# STM32F031C4T6 register map
File version: 1.0
Registers are 32-bit, access not given, reset 0x0 unless marked. A register's access mark holds for its fields unless they carry their own. Offsets are from the block's base; [hi:lo] are bit positions; {n}, {i} and the like mark numbered series.

## CRS
Base 0x40006C00
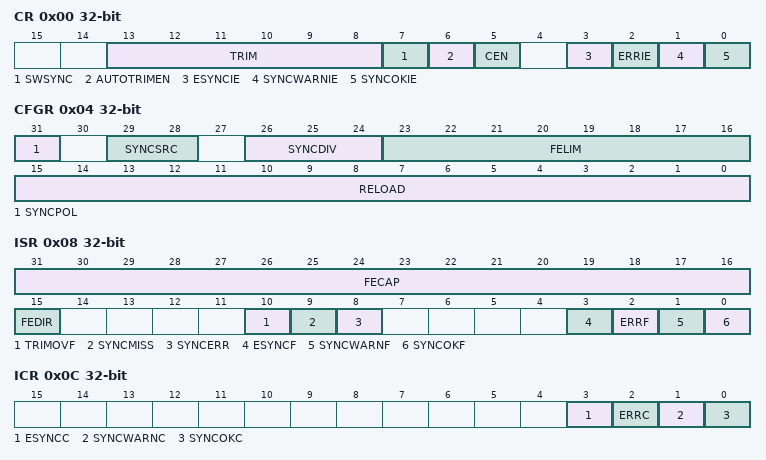
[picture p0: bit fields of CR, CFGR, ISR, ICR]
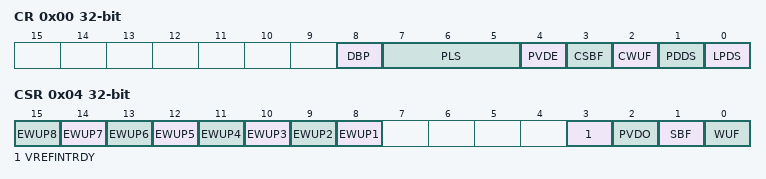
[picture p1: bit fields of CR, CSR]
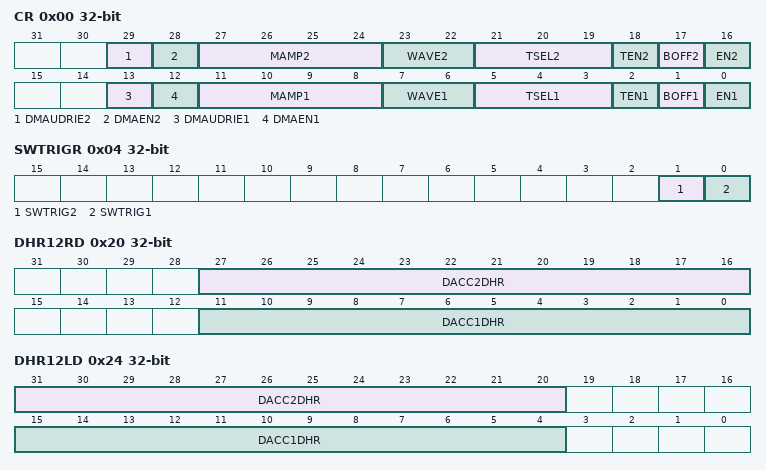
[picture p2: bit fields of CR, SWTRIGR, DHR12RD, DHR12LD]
0x00 CR
  [13:8] TRIM, [7] SWSYNC, [6] AUTOTRIMEN, [5] CEN, [3] ESYNCIE, [2] ERRIE, [1] SYNCWARNIE, [0] SYNCOKIE
0x04 CFGR
  [31] SYNCPOL, [29:28] SYNCSRC, [26:24] SYNCDIV, [23:16] FELIM, [15:0] RELOAD
0x08 ISR
  [31:16] FECAP, [15] FEDIR, [10] TRIMOVF, [9] SYNCMISS, [8] SYNCERR, [3] ESYNCF, [2] ERRF, [1] SYNCWARNF, [0] SYNCOKF
0x0C ICR
  [3] ESYNCC, [2] ERRC, [1] SYNCWARNC, [0] SYNCOKC

## PWR
Base 0x40007000
0x00 CR
  [8] DBP, [7:5] PLS, [4] PVDE, [3] CSBF, [2] CWUF, [1] PDDS, [0] LPDS
0x04 CSR
  [n+7] EWUP{n} (n=1..8), [3] VREFINTRDY, [2] PVDO, [1] SBF, [0] WUF

## DAC
Base 0x40007400
0x00 CR
  [29] DMAUDRIE2, [28] DMAEN2, [27:24] MAMP2, [23:22] WAVE2, [21:19] TSEL2, [18] TEN2, [17] BOFF2, [16] EN2, [13] DMAUDRIE1, [12] DMAEN1, [11:8] MAMP1, [7:6] WAVE1, [5:3] TSEL1, [2] TEN1, [1] BOFF1, [0] EN1
0x04 SWTRIGR
  [1] SWTRIG2, [0] SWTRIG1
0x08 DHR12R1
  [11:0] DACC1DHR
0x0C DHR12L1
  [15:4] DACC1DHR
0x10 DHR8R1
  [7:0] DACC1DHR
0x14 DHR12R2
  [11:0] DACC2DHR
0x18 DHR12L2
  [15:4] DACC2DHR
0x1C DHR8R2
  [7:0] DACC2DHR
0x20 DHR12RD
  [27:16] DACC2DHR, [11:0] DACC1DHR
0x24 DHR12LD
  [31:20] DACC2DHR, [15:4] DACC1DHR
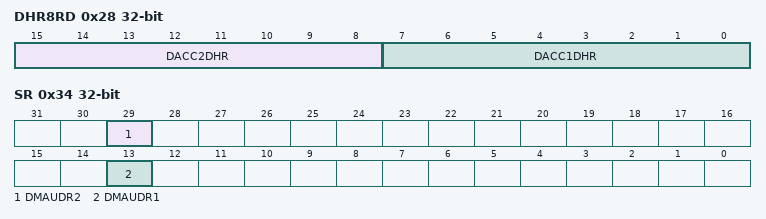
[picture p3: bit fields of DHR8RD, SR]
0x28 DHR8RD
  [15:8] DACC2DHR, [7:0] DACC1DHR
0x2C DOR1
  [11:0] DACC1DOR
0x30 DOR2
  [11:0] DACC2DOR
0x34 SR
  [29] DMAUDR2, [13] DMAUDR1

## CEC
Base 0x40007800
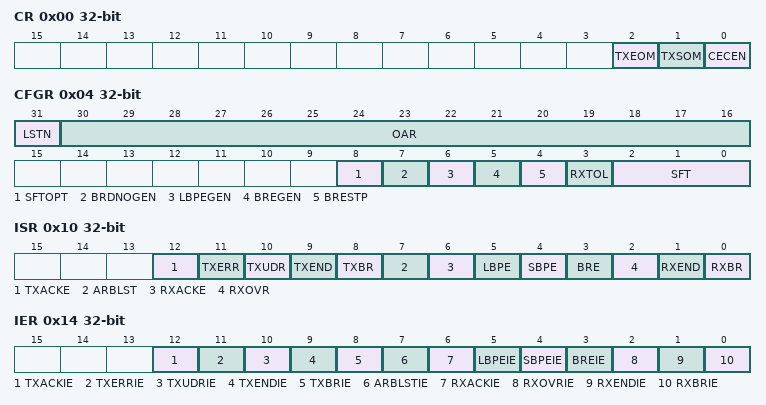
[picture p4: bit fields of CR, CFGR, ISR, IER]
0x00 CR
  [2] TXEOM, [1] TXSOM, [0] CECEN
0x04 CFGR
  [31] LSTN, [30:16] OAR, [8] SFTOPT, [7] BRDNOGEN, [6] LBPEGEN, [5] BREGEN, [4] BRESTP, [3] RXTOL, [2:0] SFT
0x08 TXDR
  [7:0] TXD
0x0C RXDR
  [7:0] RXD
0x10 ISR
  [12] TXACKE, [11] TXERR, [10] TXUDR, [9] TXEND, [8] TXBR, [7] ARBLST, [6] RXACKE, [5] LBPE, [4] SBPE, [3] BRE, [2] RXOVR, [1] RXEND, [0] RXBR
0x14 IER
  [12] TXACKIE, [11] TXERRIE, [10] TXUDRIE, [9] TXENDIE, [8] TXBRIE, [7] ARBLSTIE, [6] RXACKIE, [5] LBPEIE, [4] SBPEIE, [3] BREIE, [2] RXOVRIE, [1] RXENDIE, [0] RXBRIE

## SYSCFGCOMP
Base 0x40010000
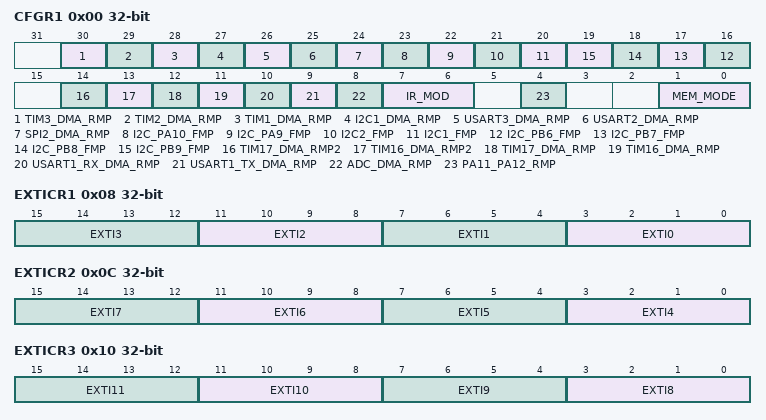
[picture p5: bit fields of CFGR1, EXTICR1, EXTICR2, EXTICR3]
0x00 CFGR1
  [30] TIM3_DMA_RMP, [29] TIM2_DMA_RMP, [28] TIM1_DMA_RMP, [27] I2C1_DMA_RMP, [26] USART3_DMA_RMP, [25] USART2_DMA_RMP, [24] SPI2_DMA_RMP, [23] I2C_PA10_FMP, [22] I2C_PA9_FMP, [21] I2C2_FMP, [20] I2C1_FMP, [n+10] I2C_PB{n}_FMP (n=6..9), [14] TIM17_DMA_RMP2, [13] TIM16_DMA_RMP2, [12] TIM17_DMA_RMP, [11] TIM16_DMA_RMP, [10] USART1_RX_DMA_RMP, [9] USART1_TX_DMA_RMP, [8] ADC_DMA_RMP, [7:6] IR_MOD, [4] PA11_PA12_RMP, [1:0] MEM_MODE
0x08 EXTICR1
  [4n+3:4n] EXTI{n} (n=0..3)
0x0C EXTICR2
  [4n-13:4n-16] EXTI{n} (n=4..7)
0x10 EXTICR3
  [4n-29:4n-32] EXTI{n} (n=8..11)
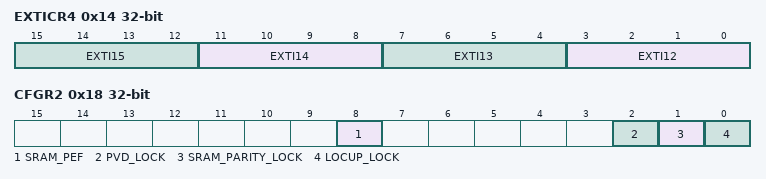
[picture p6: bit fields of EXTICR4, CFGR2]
0x14 EXTICR4
  [4n-45:4n-48] EXTI{n} (n=12..15)
0x18 CFGR2
  [8] SRAM_PEF, [2] PVD_LOCK, [1] SRAM_PARITY_LOCK, [0] LOCUP_LOCK

## EXTI
Base 0x40010400
0x00 IMR
  [31:0] IM
0x04 EMR
  [31:0] EM
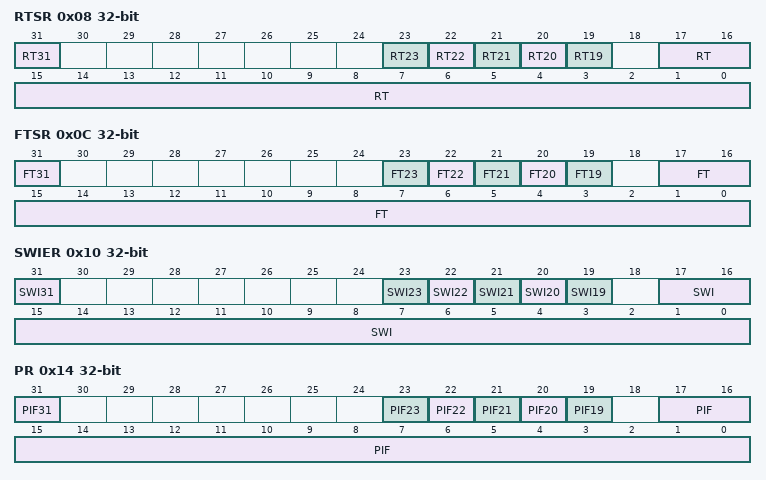
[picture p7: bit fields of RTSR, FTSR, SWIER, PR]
0x08 RTSR
  [31] RT31, [n] RT{n} (n=19..23), [17:0] RT
0x0C FTSR
  [31] FT31, [n] FT{n} (n=19..23), [17:0] FT
0x10 SWIER
  [31] SWI31, [n] SWI{n} (n=19..23), [17:0] SWI
0x14 PR
  [31] PIF31, [n] PIF{n} (n=19..23), [17:0] PIF

## ADC
Base 0x40012400
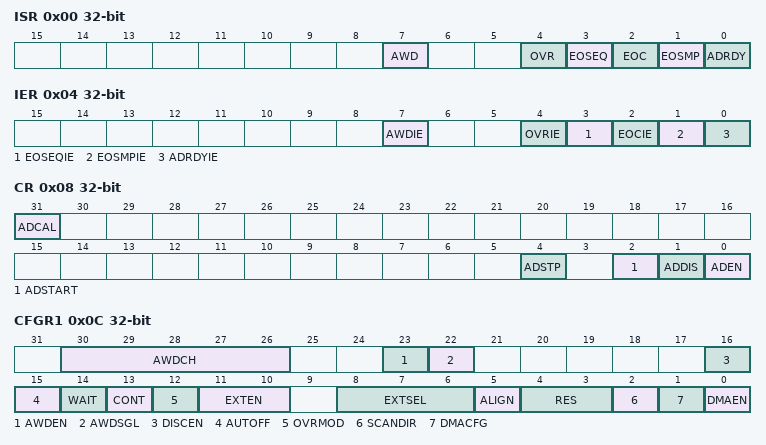
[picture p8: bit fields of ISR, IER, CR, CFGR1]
0x00 ISR
  [7] AWD, [4] OVR, [3] EOSEQ, [2] EOC, [1] EOSMP, [0] ADRDY
0x04 IER
  [7] AWDIE, [4] OVRIE, [3] EOSEQIE, [2] EOCIE, [1] EOSMPIE, [0] ADRDYIE
0x08 CR
  [31] ADCAL, [4] ADSTP, [2] ADSTART, [1] ADDIS, [0] ADEN
0x0C CFGR1
  [30:26] AWDCH, [23] AWDEN, [22] AWDSGL, [16] DISCEN, [15] AUTOFF, [14] WAIT, [13] CONT, [12] OVRMOD, [11:10] EXTEN, [8:6] EXTSEL, [5] ALIGN, [4:3] RES, [2] SCANDIR, [1] DMACFG, [0] DMAEN
0x10 CFGR2
  [31:30] CKMODE
0x14 SMPR
  [2:0] SMP
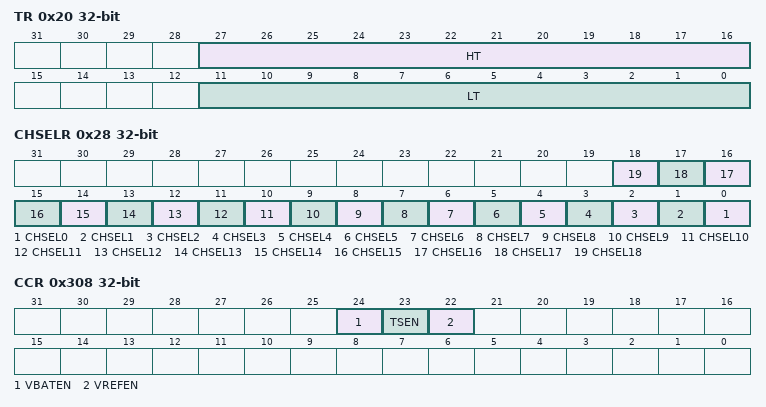
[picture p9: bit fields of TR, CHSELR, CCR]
0x20 TR
  [27:16] HT, [11:0] LT
0x28 CHSELR
  [n] CHSEL{n} (n=0..18)
0x40 DR
  [15:0] DATA
0x308 CCR
  [24] VBATEN, [23] TSEN, [22] VREFEN

## TIM1
Base 0x40012C00
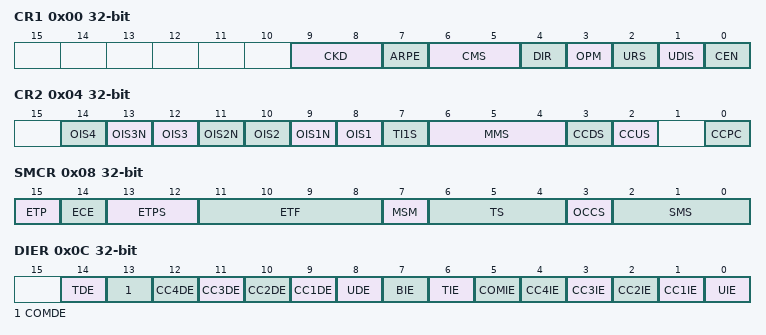
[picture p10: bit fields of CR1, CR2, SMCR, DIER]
0x00 CR1
  [9:8] CKD, [7] ARPE, [6:5] CMS, [4] DIR, [3] OPM, [2] URS, [1] UDIS, [0] CEN
0x04 CR2
  [2n+6] OIS{n} (n=1..4), [13] OIS3N, [11] OIS2N, [9] OIS1N, [7] TI1S, [6:4] MMS, [3] CCDS, [2] CCUS, [0] CCPC
0x08 SMCR
  [15] ETP, [14] ECE, [13:12] ETPS, [11:8] ETF, [7] MSM, [6:4] TS, [3] OCCS, [2:0] SMS
0x0C DIER
  [14] TDE, [13] COMDE, [n+8] CC{n}DE (n=1..4), [8] UDE, [7] BIE, [6] TIE, [5] COMIE, [n] CC{n}IE (n=1..4), [0] UIE
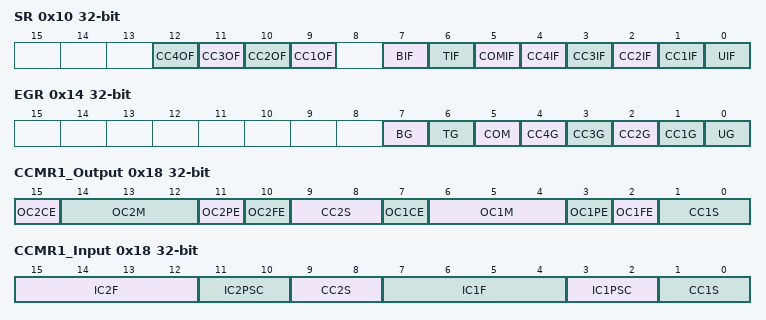
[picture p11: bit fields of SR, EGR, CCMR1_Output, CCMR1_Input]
0x10 SR
  [n+8] CC{n}OF (n=1..4), [7] BIF, [6] TIF, [5] COMIF, [n] CC{n}IF (n=1..4), [0] UIF
0x14 EGR
  [7] BG, [6] TG, [5] COM, [n] CC{n}G (n=1..4), [0] UG
0x18 CCMR1_Output
  [15] OC2CE, [14:12] OC2M, [11] OC2PE, [10] OC2FE, [9:8] CC2S, [7] OC1CE, [6:4] OC1M, [3] OC1PE, [2] OC1FE, [1:0] CC1S
0x18 CCMR1_Input
  [15:12] IC2F, [11:10] IC2PSC, [9:8] CC2S, [7:4] IC1F, [3:2] IC1PSC, [1:0] CC1S
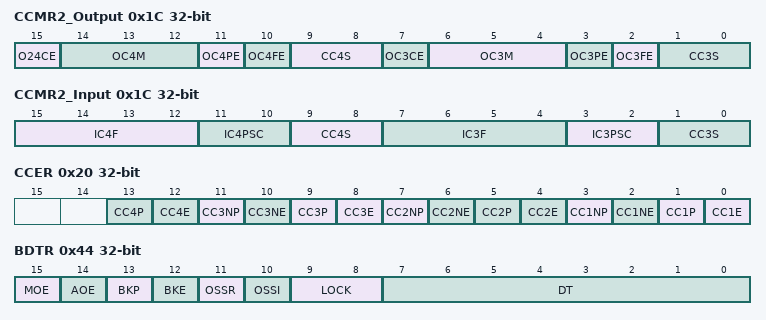
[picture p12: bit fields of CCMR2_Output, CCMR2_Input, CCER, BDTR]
0x1C CCMR2_Output
  [15] O24CE, [14:12] OC4M, [11] OC4PE, [10] OC4FE, [9:8] CC4S, [7] OC3CE, [6:4] OC3M, [3] OC3PE, [2] OC3FE, [1:0] CC3S
0x1C CCMR2_Input
  [15:12] IC4F, [11:10] IC4PSC, [9:8] CC4S, [7:4] IC3F, [3:2] IC3PSC, [1:0] CC3S
0x20 CCER
  [4n-3] CC{n}P (n=1..4), [4n-4] CC{n}E (n=1..4), [11] CC3NP, [10] CC3NE, [7] CC2NP, [6] CC2NE, [3] CC1NP, [2] CC1NE
0x24 CNT
  [15:0] CNT
0x28 PSC
  [15:0] PSC
0x2C ARR
  [15:0] ARR
0x30 RCR
  [7:0] REP
{0x30+4i} CCR{i} (i=1..4)
  [15:0] CCR{i}
0x44 BDTR
  [15] MOE, [14] AOE, [13] BKP, [12] BKE, [11] OSSR, [10] OSSI, [9:8] LOCK, [7:0] DT
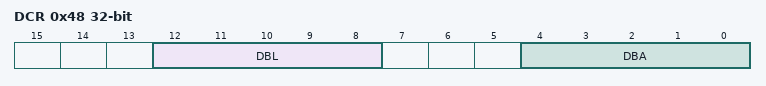
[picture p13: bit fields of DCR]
0x48 DCR
  [12:8] DBL, [4:0] DBA
0x4C DMAR
  [15:0] DMAB
